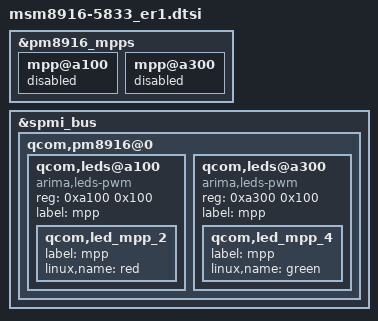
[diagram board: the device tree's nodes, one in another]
#include "msm8916-mtp-arima-5833.dtsi"

// [5833][RG_LED][akenhsu] Porting arima PWM LED on PMIC 8916 20160322 BEGIN
&pm8916_mpps {
	mpp@a100 { /* MPP 2 */
		status = "disabled";
	};
	mpp@a300 { /* MPP 4 */
		status = "disabled";
	};
};

&spmi_bus {
	qcom,pm8916@0 {
		qcom,leds@a100 {
			status = "okay";
			compatible = "arima,leds-pwm";
			reg = <0xa100 0x100>;
			label = "mpp";
			qcom,led_mpp_2 {
				label = "mpp";
				linux,name = "red";
			};
		};
		qcom,leds@a300 {
			status = "okay";
			compatible = "arima,leds-pwm";
			reg = <0xa300 0x100>;
			label = "mpp";
			qcom,led_mpp_4 {
				label = "mpp";
				linux,name = "green";
			};
		};
	};
};
// [5833][RG_LED][akenhsu] 20160322 END
